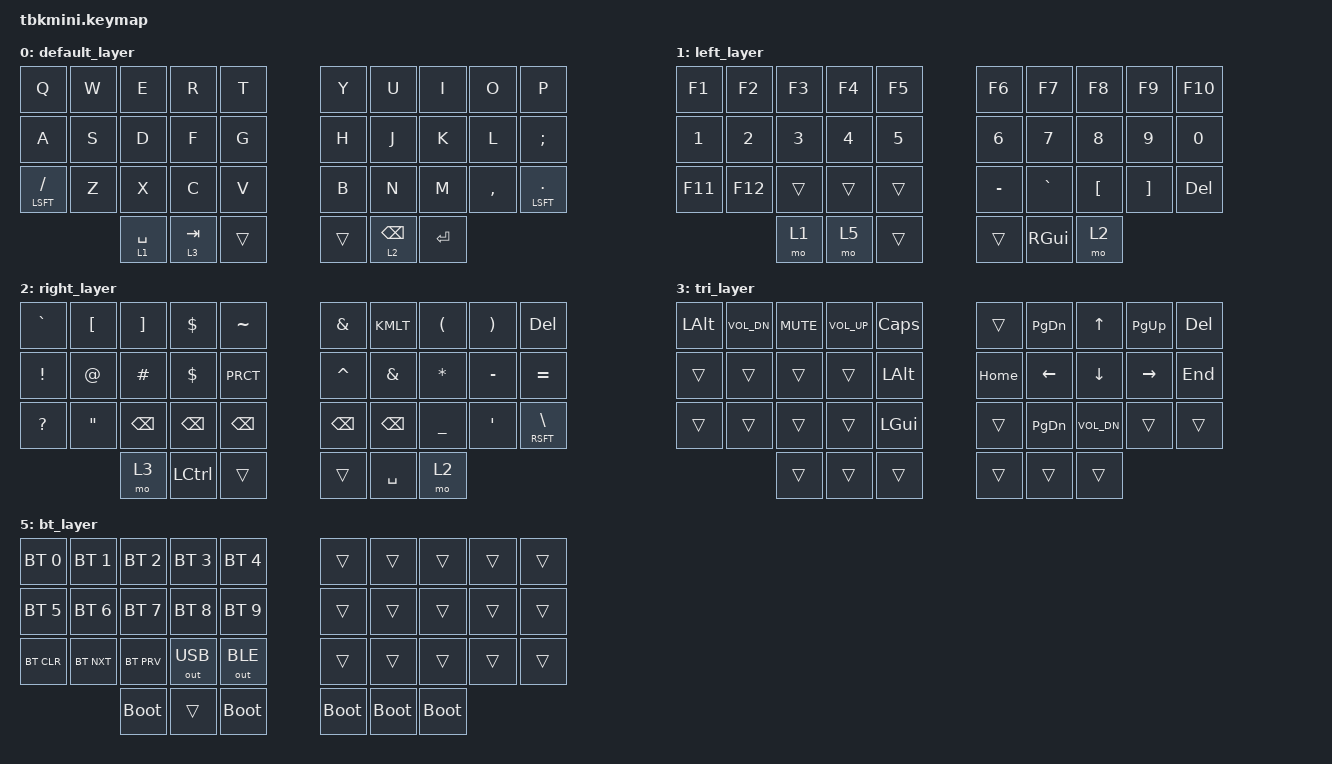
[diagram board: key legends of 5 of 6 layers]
#include <behaviors.dtsi>
#include <dt-bindings/zmk/keys.h>
#include <dt-bindings/zmk/outputs.h>
#include <dt-bindings/zmk/bt.h>

#define DEFAULT 0
#define GAME 1
#define NUM 2
#define SYM 3
#define FUN 4
#define NAV 5
#define MSE 6
#define MED 7

&lt {
  tapping-term-ms = <300>;
  quick_tap_ms = <200>;
  flavor = "balanced";
};

/ {
  chosen {
    zmk,matrix_transform = &skeletyl_transform;
  };

  behaviors {
    hm: homerow_mods {
      compatible = "zmk,behavior-hold-tap";
      label = "HOMEROW_MODS";
      #binding-cells = <2>;
      tapping-term-ms = <150>;
      quick_tap_ms = <150>;
      flavor = "tap-preferred";
      bindings = <&kp>, <&kp>;
    };
    lm: left_hand_positional_hold_tap {
      compatible = "zmk,behavior-hold-tap";
      label = "LEFT_HOMEROW_MODS";
      #binding-cells = <2>;
      flavor = "tap-unless-interrupted";
      tapping-term-ms = <200>;
      quick-tap-ms = <200>;
      bindings = <&kp>, <&kp>;
      hold-trigger-key-positions = <5 6 7 8 9 15 16 17 18 19 25 26 27 28 29>;
    };
    rm: right_hand_positional_hold_tap {
      compatible = "zmk,behavior-hold-tap";
      label = "RIGHT_HOMEROW_MODS";
      #binding-cells = <2>;
      flavor = "tap-unless-interrupted";
      tapping-term-ms = <200>;
      quick-tap-ms = <200>;
      bindings = <&kp>, <&kp>;
      hold-trigger-key-positions = <0 1 2 3 4 10 11 12 13 14 20 21 22 23 24>;
    };
  };

combos {
        compatible = "zmk,combos";
        combo_esc {
            timeout-ms = <30>;
            key-positions = <12 13>;
            bindings = <&kp ESC>;
            slow-release;
        };

           combo_ent {
            timeout-ms = <30>;
            key-positions = <13 24>;
            bindings = <&kp RET>;
            slow-release;
        };

	   combo_bksp {
            timeout-ms = <30>;
            key-positions = <10 20>;
            bindings = <&kp BKSP>;
            slow-release;
        };

           combo_lalt {
            timeout-ms = <30>;
            key-positions = <1 12>;
            bindings = <&kp LALT>;
            slow-release;
        };

           combo_colemak {
            timeout-ms = <30>;
            key-positions = <5 25>;
            bindings = <&tog 4>;
            slow-release;
        };

	combo_lalt {
            timeout-ms = <30>;
            key-positions = <1 12>;
            bindings = <&kp LALT>;
            slow-release;
        };
	combo_lgui {
            timeout-ms = <30>;
            key-positions = <1 13>;
            bindings = <&kp LGUI>;
            slow-release;
        };
	combo_lctl {
            timeout-ms = <30>;
            key-positions = <2 13>;
            bindings = <&kp LCTL>;
            slow-release;
        };
	combo_ralt {
            timeout-ms = <30>;
            key-positions = <8 17>;
            bindings = <&kp RALT>;
            slow-release;
        };
	combo_rgui {
            timeout-ms = <30>;
            key-positions = <8 16>;
            bindings = <&kp RGUI>;
            slow-release;
        };
	combo_rctl {
            timeout-ms = <30>;
            key-positions = <7 16>;
            bindings = <&kp RCTL>;
            slow-release;
        };
	combo_laltgui {
            timeout-ms = <30>;
            key-positions = <11 2 3>;
            bindings = <&kp LA(LGUI)>;
            slow-release;
        };
	combo_laltctl {
            timeout-ms = <30>;
            key-positions = <1 12 3>;
            bindings = <&kp LA(LCTL)>;
            slow-release;
        };
	combo_lguictl {
            timeout-ms = <30>;
            key-positions = <1 2 13>;
            bindings = <&kp LG(LCTL)>;
	    slow-release;
	};
	combo_raltgui {
	    timeout-ms = <30>;
	    key-positions = <6 7 18>;
	    bindings = <&kp RA(RGUI)>;
	    slow-release;
	};
	combo_raltctl {
	    timeout-ms = <30>;
	    key-positions = <6 17 8>;
	    bindings = <&kp RA(RCTL)>;
	    slow-release;
	};
	combo_rguictl {
	    timeout-ms = <30>;
	    key-positions = <16 7 8>;
	    bindings = <&kp RG(RCTL)>;
	    slow-release;
	};

                        // home row combos

                // left side

           combo_lhome_alt {
            timeout-ms = <30>;
            key-positions = <31 13>;
            bindings = <&kp LALT>;
            slow-release;
        };

           combo_lhome_altgui {
            timeout-ms = <30>;
            key-positions = <31 12 13>;
            bindings = <&kp LA(LGUI)>;
            slow-release;
        };

           combo_lhome_altctl {
            timeout-ms = <30>;
            key-positions = <31 11 13>;
            bindings = <&kp LA(LCTL)>;
            slow-release;
        };

           combo_lhome_altguictl {
            timeout-ms = <30>;
            key-positions = <31 11 12 13>;
            bindings = <&kp LA(LG(LCTRL))>;
            slow-release;
        };

           combo_lhome_gui {
            timeout-ms = <30>;
            key-positions = <31 12>;
            bindings = <&kp LGUI>;
            slow-release;
        };

           combo_lhome_guictl {
            timeout-ms = <30>;
            key-positions = <31 11 12>;
            bindings = <&kp LG(LCTRL)>;
            slow-release;
        };

           combo_lhome_ctl {
            timeout-ms = <30>;
            key-positions = <31 11>;
            bindings = <&kp LCTRL>;
            slow-release;
        };

                // right side

           combo_rhome_alt {
            timeout-ms = <30>;
            key-positions = <34 16>;
            bindings = <&kp RALT>;
            slow-release;
        };

           combo_rhome_altgui {
            timeout-ms = <30>;
            key-positions = <34 17 16>;
            bindings = <&kp RA(RGUI)>;
            slow-release;
        };

           combo_rhome_altctl {
            timeout-ms = <30>;
            key-positions = <34 18 16>;
            bindings = <&kp RA(RCTL)>;
            slow-release;
        };

           combo_rhome_altguictl {
            timeout-ms = <30>;
            key-positions = <34 18 17 16>;
            bindings = <&kp RA(RG(RCTRL))>;
            slow-release;
        };

           combo_rhome_gui {
            timeout-ms = <30>;
            key-positions = <34 17>;
            bindings = <&kp RGUI>;
            slow-release;
        };

           combo_rhome_guictl {
            timeout-ms = <30>;
            key-positions = <34 18 17>;
            bindings = <&kp RG(RCTRL)>;
            slow-release;
        };

           combo_rhome_ctl {
            timeout-ms = <30>;
            key-positions = <34 18>;
            bindings = <&kp RCTRL>;
            slow-release;
        };
    };

  keymap {
        compatible = "zmk,keymap";

        default_layer {
		bindings = <
		&kp Q &kp W &kp E &kp R &kp T 						&kp Y &kp U  &kp I    &kp O   &kp P
		&kp A &kp S &kp D &kp F &kp G 			        	        &kp H &kp J &kp K &kp L &kp SCLN
		&mt LSFT FSLH &kp Z &kp X &kp C &kp V 				        &kp B &kp N &kp M  &kp CMMA &mt LSFT DOT
					&lt 1 SPC &lt 3 TAB  &trans &trans 			&lt 2 BKSP &kp RET 
		>;
	};

	left_layer {
		bindings = <
		&kp F1    &kp F2        &kp F3      &kp F4        &kp F5		&kp F6     &kp F7  &kp F8   &kp F9     &kp F10
		&kp N1    &kp N2        &kp N3      &kp N4        &kp N5		&kp N6     &kp N7  &kp N8   &kp N9     &kp N0
		&kp F11    &kp F12 	&trans      &trans        &trans        	&kp MINUS &kp GRAVE &kp LBKT &kp RBKT  &kp DEL
					   &mo 1  &mo 5  &trans &trans					&kp RGUI &mo 2 
		>;
	};

	right_layer {
		bindings = <
		&kp GRAVE  &kp LBKT &kp RBKT  &kp DLLR  &kp TILDE    			&kp AMPS  &kp KMLT &kp LPRN &kp RPRN &kp DEL
		&kp EXCL  &kp AT  &kp HASH  &kp DLLR  &kp PRCT 			&kp CARET &kp AMPS  &kp STAR  &kp MINUS   &kp EQUAL
		&kp QMARK  &kp DQT &kp BKSP &kp BKSP   &kp BKSP    			&kp BKSP &kp BKSP &kp UNDER &kp SQT  &mt RSFT BSLH
					&mo 3 &kp LCTL &trans &trans 				&kp SPC  &mo 2 
		>;
	};

	tri_layer {
		bindings = <
		&kp LALT  &kp K_VOL_DN &kp K_MUTE &kp K_VOL_UP &kp CAPS			&trans &kp PG_DN   &kp UP   &kp PG_UP  &kp DEL
		&trans  &trans &trans &trans &kp LALT					&kp HOME &kp LEFT  &kp DOWN &kp RIGHT &kp END
		&trans  &trans &trans &trans &kp LGUI   				&trans &kp PG_DN  &kp K_VOL_DN  &trans &trans
					 &trans &trans &trans  				&trans &trans &trans
		>;
	};

	quad_layer {
		bindings = <
		&kp Q &kp W &kp F &kp P &kp B 						&kp J &kp L  &kp U    &kp Y   &kp SCLN
		&kp A &kp R &kp S &kp T &kp G 			        	        &kp M &kp N &kp E &kp I &kp O
		&mt LSFT Z &kp X &kp C &kp D &kp V 				        &kp K &kp H &kp CMMA &kp DOT &mt LSFT FSLH
					&lt 1 SPC &lt 3 TAB  				&lt 2 BKSP &kp RET 
		>;
	};
	bt_layer {
		bindings = <
		&bt BT_SEL 0 &bt BT_SEL 1 &bt BT_SEL 2 &bt BT_SEL 3 &bt BT_SEL 4        &trans &trans &trans &trans &trans
		&bt BT_SEL 5 &bt BT_SEL 6 &bt BT_SEL 7 &bt BT_SEL 8 &bt BT_SEL 9        &trans &trans &trans &trans &trans
		&bt BT_CLR  &bt BT_NXT &bt BT_PRV &out OUT_USB &out OUT_BLE 	       	&trans &trans &trans &trans &trans
					&bootloader &trans  		&bootloader &bootloader		&bootloader &bootloader
		>;
	};
    };
};
